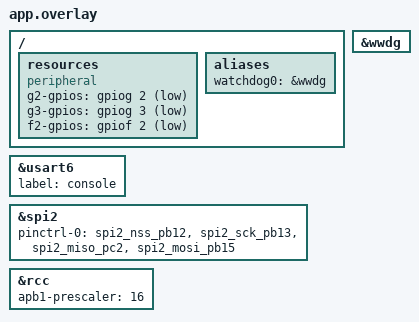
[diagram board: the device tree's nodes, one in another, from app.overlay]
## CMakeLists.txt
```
# SPDX-License-Identifier: Apache-2.0

cmake_minimum_required(VERSION 3.20.0)
find_package(Zephyr REQUIRED HINTS $ENV{ZEPHYR_BASE})
project(platform)

FILE(GLOB sources src/*.c)
target_sources(app PRIVATE ${sources})

add_subdirectory(module)
add_subdirectory(state_machine)
zephyr_include_directories(
	${CMAKE_CURRENT_LIST_DIR}/module
	${CMAKE_CURRENT_LIST_DIR}/state_machine
	)
add_subdirectory(qpc)
```

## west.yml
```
# The west manifest file for upstream Zephyr.
#
# The per-installation west configuration file, .west/config, sets the
# path to the project containing this file in the [manifest] section's
# "path" variable.
#
# You are free to create your own manifest files and put them in any
# repository you want, to create your own custom Zephyr installations.
# For example, you could create a manifest file in your own out of
# tree application directory, which would pull this zephyr repository
# in as an ordinary project.
#
# You can pass your manifest repositories to west init when creating a
# new Zephyr installation. See the west documentation for more
# information.

manifest:
  defaults:
    remote: upstream

  remotes:
    - name: upstream
      url-base: https://github.com/zephyrproject-rtos
  #
  # Please add items below based on alphabetical order
  # zephyr-keep-sorted-start re(^\s+\- name:)
  projects:
      # Zephyr 必須放第一個，west 才會正確設定 base
    - name: zephyr
      path: zephyr
      revision: main
      import: false
    - name: cmsis
      revision: 512cc7e895e8491696b61f7ba8066b4a182569b8
      path: modules/hal/cmsis
      groups:
        - hal
    - name: hal_stm32
      revision: 1e753266ddfb4b07a8a0b1ec566e9637ea45d5ef
      path: modules/hal/stm32
      groups:
        - hal
  # zephyr-keep-sorted-stop

  self:
    path: .
    west-commands: zephyr/scripts/west-commands.yml  # 指定 west 指令定義位置
```

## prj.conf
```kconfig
CONFIG_GPIO=y
CONFIG_SERIAL=y
CONFIG_UART_INTERRUPT_DRIVEN=y
CONFIG_HEAP_MEM_POOL_SIZE=256
CONFIG_I2C=y
CONFIG_SPI=y
CONFIG_LOG=y
CONFIG_LOG_MODE_IMMEDIATE=y
CONFIG_WDT_LOG_LEVEL_DBG=y
CONFIG_WATCHDOG=y
CONFIG_WDT_DISABLE_AT_BOOT=n
```

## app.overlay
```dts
/*
 * Copyright (c) 2023 Martin Jäger / Libre Solar
 *
 * SPDX-License-Identifier: Apache-2.0
 */

/ {
	resources:resources {
		compatible = "peripheral";
		g2-gpios = <&gpiog 2 GPIO_ACTIVE_LOW>;
		g3-gpios = <&gpiog 3 GPIO_ACTIVE_LOW>;
		f2-gpios = <&gpiof 2 GPIO_ACTIVE_LOW>;
	};
	aliases {
		watchdog0 = &wwdg;
	};
};

&usart6 {
	label = "console";
};

&spi2 {
	pinctrl-0 = < &spi2_nss_pb12 &spi2_sck_pb13 &spi2_miso_pc2 &spi2_mosi_pb15 >;
};

&rcc {
	apb1-prescaler = <16>;
};

&wwdg {
	status = "okay";
};
```

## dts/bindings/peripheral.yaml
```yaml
# Copyright (c) 2023 Libre Solar Technologies GmbH
# SPDX-License-Identifier: Apache-2.0

description: project's peripheral definition

compatible: "peripheral"

properties:
  g2-gpios:
    type: phandle-array
    required: true
    description: |
      LED 0
  g3-gpios:
    type: phandle-array
    required: true
    description: |
      LED 1
  f2-gpios:
    type: phandle-array
    required: true
    description: |
      SW 0
```

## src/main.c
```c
/*
 * Copyright (c) 2023 Libre Solar Technologies GmbH
 *
 * SPDX-License-Identifier: Apache-2.0
 */

#include <stdio.h>
#include <zephyr/devicetree.h>
#include <zephyr/drivers/gpio.h>
#include <zephyr/kernel.h>
#include "module.h"

static void SW_handler(const struct device *dev, struct gpio_callback *cb, uint32_t pins)
{
	uint8_t gpio_pin = 31 - __builtin_clz(pins);
	int ret = gpio_pin_get(dev, gpio_pin);

	if(ret)
	{
		LED_ON();
	}
	else
	{
		LED_OFF();
	}
}

int main(void)
{
	int ret = 0;

	printk("Hello World! %s\n This is Git branch\n", CONFIG_BOARD);

	ret = LED_Init();
	if(ret)
	{
		printk("LED_Init error:%d\n", ret);
	}

	ret = SW_Init(SW_handler);
	if(ret)
	{
		printk("SW_Init error:%d\n", ret);
	}

	if(SW_Status())
	{
		LED_ON();
	}
	else
	{
		LED_OFF();
	}

	ExtEEPROM_Cmp();
	ExtEEPROM_Dump();

	ret = ExtFlash_Init();
	if(ret)
	{
		printk("ExtFlash_Init error:%d\n", ret);
	}
	ExtFlash_Cmp();
	ExtFlash_Dump(0,16);

	ret = Watchdog_Init();
	if(ret)
	{
		printk("Watchdog_Init error:%d\n", ret);
	}

	while(1)
	{
		Watchdog_Feed();
		k_sleep(K_MSEC(50));
	}
	return 0;
}
```
